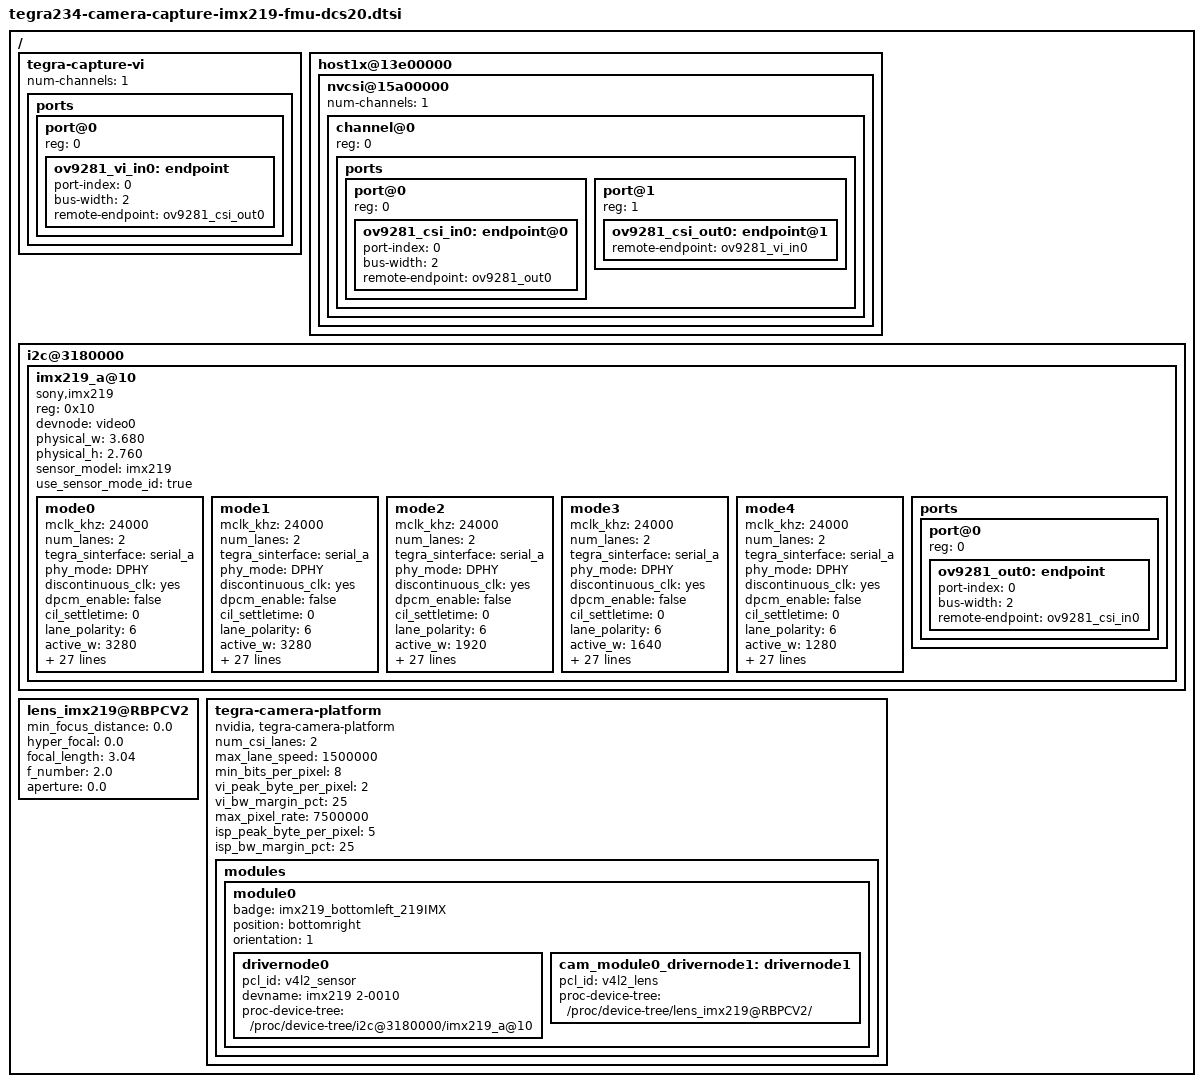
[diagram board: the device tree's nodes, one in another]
/*
 * Copyright (c) 2015-2019, NVIDIA CORPORATION.  All rights reserved.
 *
 * This program is free software; you can redistribute it and/or modify
 * it under the terms of the GNU General Public License as published by
 * the Free Software Foundation; either version 2 of the License, or
 * (at your option) any later version.
 *
 * This program is distributed in the hope that it will be useful, but WITHOUT
 * ANY WARRANTY; without even the implied warranty of MERCHANTABILITY or
 * FITNESS FOR A PARTICULAR PURPOSE.  See the GNU General Public License for
 * more details.
 *
 * You should have received a copy of the GNU General Public License
 * along with this program.  If not, see <http://www.gnu.org/licenses/>.
 */

#include <dt-bindings/media/camera.h>
/ {
	tegra-capture-vi  {
			num-channels = <1>;
			ports {
				status="okay";
				#address-cells = <1>;
				#size-cells = <0>;
				port@0 {
					status="okay";
					reg = <0>;
					ov9281_vi_in0: endpoint {
						status="okay";
						port-index = <0>;
						bus-width = <2>;
						remote-endpoint = <&ov9281_csi_out0>;
					};
				};
			};
	};
	
	host1x@13e00000 {	
		nvcsi@15a00000 {
			num-channels = <1>;
			#address-cells = <1>;
			#size-cells = <0>;
			status="okay";
			channel@0 {
				reg = <0>;
				status="okay";
				ports {
					#address-cells = <1>;
					#size-cells = <0>;
					status="okay";
					port@0 {
						reg = <0>;
						status="okay";
						ov9281_csi_in0: endpoint@0 {
							status="okay";
							port-index = <0>;
							bus-width = <2>;
							remote-endpoint = <&ov9281_out0>;
						};
					};
					port@1 {
						reg = <1>;
						status="okay";
						ov9281_csi_out0: endpoint@1 {
							status="okay";
							remote-endpoint = <&ov9281_vi_in0>;
						};
					};
				};
			};
		};	
	};

	i2c@3180000 {  				 	
		imx219_a@10 {
			compatible = "sony,imx219";
			/* I2C device address */
			reg = <0x10>;

			/* V4L2 device node location */
			devnode = "video0";

			/* Physical dimensions of sensor */
			physical_w = "3.680";
			physical_h = "2.760";

			sensor_model = "imx219";

			use_sensor_mode_id = "true";

			mode0 { /* IMX219_MODE_3280x2464_21FPS */
				mclk_khz = "24000";
				num_lanes = "2";
				tegra_sinterface = "serial_a";
				phy_mode = "DPHY";
				discontinuous_clk = "yes";
				dpcm_enable = "false";
				cil_settletime = "0";
				lane_polarity = "6";

				active_w = "3280";
				active_h = "2464";
				mode_type = "bayer";
				pixel_phase = "rggb";
				csi_pixel_bit_depth = "10";
				readout_orientation = "90";
				line_length = "3448";
				inherent_gain = "1";
				mclk_multiplier = "9.33";
				pix_clk_hz = "182400000";

				gain_factor = "16";
				framerate_factor = "1000000";
				exposure_factor = "1000000";
				min_gain_val = "16"; /* 1.00x */
				max_gain_val = "170"; /* 10.66x */
				step_gain_val = "1";
				default_gain = "16"; /* 1.00x */
				min_hdr_ratio = "1";
				max_hdr_ratio = "1";
				min_framerate = "2000000"; /* 2.0 fps */
				max_framerate = "21000000"; /* 21.0 fps */
				step_framerate = "1";
				default_framerate = "21000000"; /* 21.0 fps */
				min_exp_time = "13"; /* us */
				max_exp_time = "683709"; /* us */
				step_exp_time = "1";
				default_exp_time = "2495"; /* us */

				embedded_metadata_height = "2";
			};
			mode1 { /* IMX219_MODE_3280x1848_28FPS */
				mclk_khz = "24000";
				num_lanes = "2";
				tegra_sinterface = "serial_a";
				phy_mode = "DPHY";
				discontinuous_clk = "yes";
				dpcm_enable = "false";
				cil_settletime = "0";
				lane_polarity = "6";

				active_w = "3280";
				active_h = "1848";
				mode_type = "bayer";
				pixel_phase = "rggb";
				csi_pixel_bit_depth = "10";
				readout_orientation = "90";
				line_length = "3448";
				inherent_gain = "1";
				mclk_multiplier = "9.33";
				pix_clk_hz = "182400000";

				gain_factor = "16";
				framerate_factor = "1000000";
				exposure_factor = "1000000";
				min_gain_val = "16"; /* 1.00x */
				max_gain_val = "170"; /* 10.66x */
				step_gain_val = "1";
				default_gain = "16"; /* 1.00x */
				min_hdr_ratio = "1";
				max_hdr_ratio = "1";
				min_framerate = "2000000"; /* 2.0 fps */
				max_framerate = "28000000"; /* 28.0 fps */
				step_framerate = "1";
				default_framerate = "28000000"; /* 28.0 fps */
				min_exp_time = "13"; /* us */
				max_exp_time = "683709"; /* us */
				step_exp_time = "1";
				default_exp_time = "2495"; /* us */

				embedded_metadata_height = "2";
			};
			mode2 { /* IMX219_MODE_1920x1080_30FPS */
				mclk_khz = "24000";
				num_lanes = "2";
				tegra_sinterface = "serial_a";
				phy_mode = "DPHY";
				discontinuous_clk = "yes";
				dpcm_enable = "false";
				cil_settletime = "0";
				lane_polarity = "6";

				active_w = "1920";
				active_h = "1080";
				mode_type = "bayer";
				pixel_phase = "rggb";
				csi_pixel_bit_depth = "10";
				readout_orientation = "90";
				line_length = "3448";
				inherent_gain = "1";
				mclk_multiplier = "9.33";
				pix_clk_hz = "182400000";

				gain_factor = "16";
				framerate_factor = "1000000";
				exposure_factor = "1000000";
				min_gain_val = "16"; /* 1.00x */
				max_gain_val = "170"; /* 10.66x */
				step_gain_val = "1";
				default_gain = "16"; /* 1.00x */
				min_hdr_ratio = "1";
				max_hdr_ratio = "1";
				min_framerate = "2000000"; /* 2.0 fps */
				max_framerate = "30000000"; /* 30.0 fps */
				step_framerate = "1";
				default_framerate = "30000000"; /* 30.0 fps */
				min_exp_time = "13"; /* us */
				max_exp_time = "683709"; /* us */
				step_exp_time = "1";
				default_exp_time = "2495"; /* us */

				embedded_metadata_height = "2";
			};

			mode3 { /* IMX219_MODE_1640x1232_30FPS */
				mclk_khz = "24000";
				num_lanes = "2";
				tegra_sinterface = "serial_a";
				phy_mode = "DPHY";
				discontinuous_clk = "yes";
				dpcm_enable = "false";
				cil_settletime = "0";
				lane_polarity = "6";

				active_w = "1640";
				active_h = "1232";
				mode_type = "bayer";
				pixel_phase = "rggb";
				csi_pixel_bit_depth = "10";
				readout_orientation = "90";
				line_length = "3448";
				inherent_gain = "1";
				mclk_multiplier = "9.33";
				pix_clk_hz = "182400000";

				gain_factor = "16";
				framerate_factor = "1000000";
				exposure_factor = "1000000";
				min_gain_val = "16"; /* 1.00x */
				max_gain_val = "170"; /* 10.66x */
				step_gain_val = "1";
				default_gain = "16"; /* 1.00x */
				min_hdr_ratio = "1";
				max_hdr_ratio = "1";
				min_framerate = "2000000"; /* 2.0 fps */
				max_framerate = "30000000"; /* 60.0 fps */
				step_framerate = "1";
				default_framerate = "30000000"; /* 60.0 fps */
				min_exp_time = "13"; /* us */
				max_exp_time = "683709"; /* us */
				step_exp_time = "1";
				default_exp_time = "2495"; /* us */

				embedded_metadata_height = "2";
			};
			mode4 { /* IMX219_MODE_1280x720_60FPS */
				mclk_khz = "24000";
				num_lanes = "2";
				tegra_sinterface = "serial_a";
				phy_mode = "DPHY";
				discontinuous_clk = "yes";
				dpcm_enable = "false";
				cil_settletime = "0";
				lane_polarity = "6";

				active_w = "1280";
				active_h = "720";
				mode_type = "bayer";
				pixel_phase = "rggb";
				csi_pixel_bit_depth = "10";
				readout_orientation = "90";
				line_length = "3448";
				inherent_gain = "1";
				mclk_multiplier = "9.33";
				pix_clk_hz = "182400000";

				gain_factor = "16";
				framerate_factor = "1000000";
				exposure_factor = "1000000";
				min_gain_val = "16"; /* 1.00x */
				max_gain_val = "170"; /* 10.66x */
				step_gain_val = "1";
				default_gain = "16"; /* 1.00x */
				min_hdr_ratio = "1";
				max_hdr_ratio = "1";
				min_framerate = "2000000"; /* 2.0 fps */
				max_framerate = "60000000"; /* 60.0 fps */
				step_framerate = "1";
				default_framerate = "60000000"; /* 60.0 fps */
				min_exp_time = "13"; /* us */
				max_exp_time = "683709"; /* us */
				step_exp_time = "1";
				default_exp_time = "2495"; /* us */

				embedded_metadata_height = "2";
			};
					ports {
						#address-cells = <1>;
						#size-cells = <0>;
						status="okay";

						port@0 {
							reg = <0>;
							status="okay";
							ov9281_out0: endpoint {
								status="okay";
								port-index = <0>;
								bus-width = <2>;
								remote-endpoint = <&ov9281_csi_in0>;
							};
						};
					};
				};
			};
		lens_imx219@RBPCV2 {
			min_focus_distance = "0.0";
			hyper_focal = "0.0";
			focal_length = "3.04";
			f_number = "2.0";
			aperture = "0.0";
		};
	};
				


/ {
	tegra-camera-platform {
		compatible = "nvidia, tegra-camera-platform";	
		/**
		* Physical settings to calculate max ISO BW
		*
		* num_csi_lanes = <>;
		* Total number of CSI lanes when all cameras are active
		*
		* max_lane_speed = <>;
		* Max lane speed in Kbit/s
		*
		* min_bits_per_pixel = <>;
		* Min bits per pixel
		*
		* vi_peak_byte_per_pixel = <>;
		* Max byte per pixel for the VI ISO case
		*
		* vi_bw_margin_pct = <>;
		* Vi bandwidth margin in percentage
		*
		* max_pixel_rate = <>;
		* Max pixel rate in Kpixel/s for the ISP ISO case
		* Set this to the highest pix_clk_hz out of all available modes.
		*
		* isp_peak_byte_per_pixel = <>;
		* Max byte per pixel for the ISP ISO case
		*
		* isp_bw_margin_pct = <>;
		* Isp bandwidth margin in percentage
		*/
		num_csi_lanes = <2>;
		max_lane_speed = <1500000>;
		min_bits_per_pixel = <8>;
		vi_peak_byte_per_pixel = <2>;
		vi_bw_margin_pct = <25>;
		max_pixel_rate = <7500000>;
		isp_peak_byte_per_pixel = <5>;
		isp_bw_margin_pct = <25>;

		/**
		* The general guideline for naming badge_info contains 3 parts, and is as follows,
		* The first part is the camera_board_id for the module; if the module is in a FFD
		* platform, then use the platform name for this part.
		* The second part contains the position of the module, ex. “rear” or “front”.
		* The third part contains the last 6 characters of a part number which is found
		* in the module's specsheet from the vender.
		*/
		modules { 
			status="okay";
			module0 {
				badge = "imx219_bottomleft_219IMX";
				position = "bottomright";
				orientation = "1";
				status="okay";
				drivernode0 {
					status="okay";
					pcl_id = "v4l2_sensor";
					devname = "imx219 2-0010";
					proc-device-tree = "/proc/device-tree/i2c@3180000/imx219_a@10";
				};
				cam_module0_drivernode1: drivernode1 {
					pcl_id = "v4l2_lens";
					proc-device-tree = "/proc/device-tree/lens_imx219@RBPCV2/";
				};
			};
		};
	};
};
